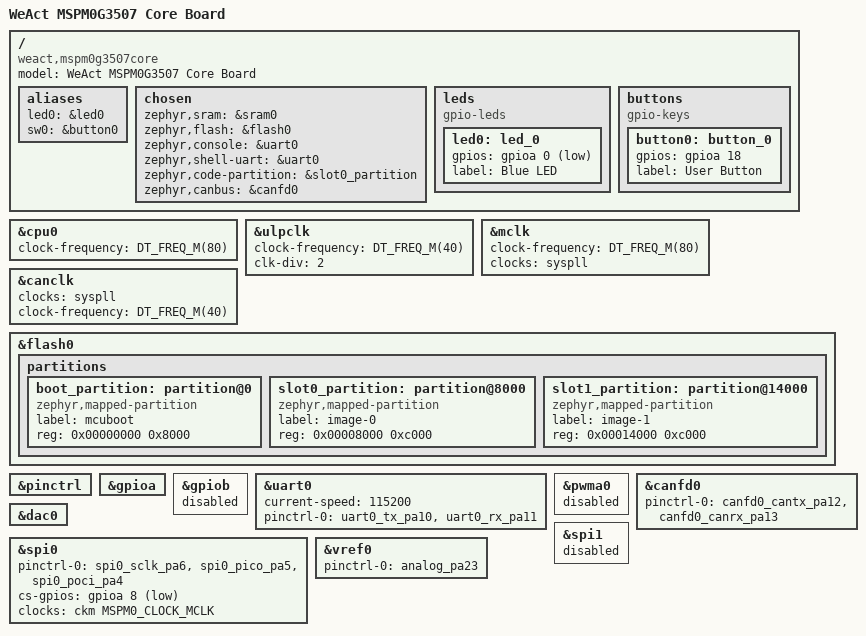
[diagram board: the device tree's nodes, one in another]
/*
 * Copyright (c) 2025 Texas Instruments
 * Copyright (c) 2025 Linumiz
 * Copyright (c) 2026 Henry Xin
 *
 * SPDX-License-Identifier: Apache-2.0
 */

/dts-v1/;

#include <ti/mspm0/g/mspm0g3507.dtsi>
#include <ti/mspm0/g/mspm0g1x0x_g3x0x-pinctrl.dtsi>
#include <zephyr/dt-bindings/clock/mspm0_clock.h>
#include <zephyr/dt-bindings/gpio/gpio.h>
#include <zephyr/dt-bindings/pwm/pwm.h>

/ {
	model = "WeAct MSPM0G3507 Core Board";
	compatible = "weact,mspm0g3507core";

	aliases {
		led0 = &led0;
		sw0 = &button0;
	};

	chosen {
		zephyr,sram = &sram0;
		zephyr,flash = &flash0;
		zephyr,console = &uart0;
		zephyr,shell-uart = &uart0;
		zephyr,code-partition = &slot0_partition;
		zephyr,canbus = &canfd0;
	};

	leds {
		compatible = "gpio-leds";

		led0: led_0 {
			gpios = <&gpioa 0 GPIO_ACTIVE_LOW>;
			label = "Blue LED";
		};
	};

	buttons {
		compatible = "gpio-keys";

		button0: button_0 {
			gpios = <&gpioa 18 GPIO_ACTIVE_HIGH>;
			label = "User Button";
		};
	};
};

&cpu0 {
	clock-frequency = <DT_FREQ_M(80)>;
};

&ulpclk {
	clock-frequency = <DT_FREQ_M(40)>;
	clk-div = <2>;
};

&mclk {
	clock-frequency = <DT_FREQ_M(80)>;
	clocks = <&syspll>;
};

&canclk {
	clocks = <&syspll>;
	clock-frequency = <DT_FREQ_M(40)>;
	status = "okay";
};

&flash0 {
	status = "okay";

	partitions {
		ranges;
		#address-cells = <1>;
		#size-cells = <1>;

		boot_partition: partition@0 {
			compatible = "zephyr,mapped-partition";
			label = "mcuboot";
			reg = <0x00000000 0x8000>;
		};

		slot0_partition: partition@8000 {
			compatible = "zephyr,mapped-partition";
			label = "image-0";
			reg = <0x00008000 0xc000>;
		};

		slot1_partition: partition@14000 {
			compatible = "zephyr,mapped-partition";
			label = "image-1";
			reg = <0x00014000 0xc000>;
		};
	};
};

&pinctrl {
	status = "okay";
};

&gpioa {
	status = "okay";
};

&gpiob {
	status = "disabled";
};

&uart0 {
	status = "okay";

	current-speed = <115200>;
	pinctrl-0 = <&uart0_tx_pa10 &uart0_rx_pa11>;
	pinctrl-names = "default";
};

&pwma0 {
	status = "disabled";
};

&canfd0 {
	status = "okay";
	pinctrl-0 = <&canfd0_cantx_pa12 &canfd0_canrx_pa13>;
	pinctrl-names = "default";
};

&dac0 {
	status = "okay";
};

&spi0 {
	status = "okay";
	pinctrl-0 = <&spi0_sclk_pa6 &spi0_pico_pa5 &spi0_poci_pa4>;
	pinctrl-names = "default";
	cs-gpios = <&gpioa 8 GPIO_ACTIVE_LOW>;
	#address-cells = <1>;
	#size-cells = <0>;
	clocks = <&ckm MSPM0_CLOCK_MCLK>;
};

&spi1 {
	status = "disabled";
};

&vref0 {
	status = "okay";
	pinctrl-0 = <&analog_pa23>;
	pinctrl-names = "default";
};
